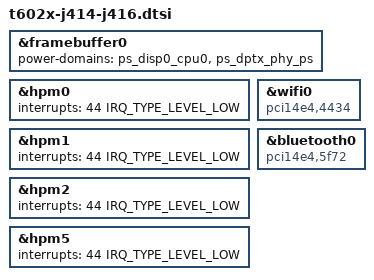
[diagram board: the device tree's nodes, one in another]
// SPDX-License-Identifier: GPL-2.0+ OR MIT
/*
 * MacBook Pro (14/16-inch, 2022)
 *
 * This file contains the parts common to J414 and J416 devices with both t6020 and t6021.
 *
 * target-type: J414s / J414c / J416s / J416c
 *
 * Copyright The Asahi Linux Contributors
 */

/*
 * These models are essentially identical to the previous generation, other than
 * the GPIO indices.
 */

#include "t600x-j314-j316.dtsi"

&framebuffer0 {
	power-domains = <&ps_disp0_cpu0>, <&ps_dptx_phy_ps>;
};

&hpm0 {
	interrupts = <44 IRQ_TYPE_LEVEL_LOW>;
};

&hpm1 {
	interrupts = <44 IRQ_TYPE_LEVEL_LOW>;
};

&hpm2 {
	interrupts = <44 IRQ_TYPE_LEVEL_LOW>;
};

&hpm5 {
	interrupts = <44 IRQ_TYPE_LEVEL_LOW>;
};

&wifi0 {
	compatible = "pci14e4,4434";
};

&bluetooth0 {
	compatible = "pci14e4,5f72";
};
